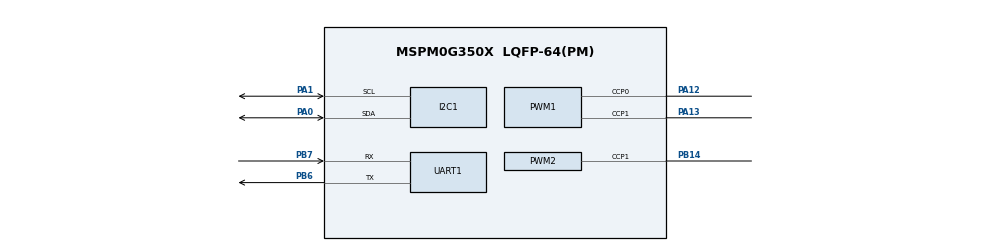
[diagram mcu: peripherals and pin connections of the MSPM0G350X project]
/**
 *
 * @cliArgs --device "MSPM0G350X" --part "Default" --package "LQFP-64(PM)" --product "mspm0_sdk@2.11.00.07"
 * @versions {"tool":"1.28.0+4712"}
 */

/**
 * Import the modules used in this configuration.
 */
const ADC12         = scripting.addModule("/ti/driverlib/ADC12", {}, false);
const ADC121        = ADC12.addInstance();
const Board         = scripting.addModule("/ti/driverlib/Board");
const GPIO          = scripting.addModule("/ti/driverlib/GPIO", {}, false);
const GPIO1         = GPIO.addInstance();
const GPIO2         = GPIO.addInstance();
const GPIO3         = GPIO.addInstance();
const I2C           = scripting.addModule("/ti/driverlib/I2C", {}, false);
const I2C1          = I2C.addInstance();
const PWM           = scripting.addModule("/ti/driverlib/PWM", {}, false);
const PWM1          = PWM.addInstance();
const PWM2          = PWM.addInstance();
const SYSCTL        = scripting.addModule("/ti/driverlib/SYSCTL");
const SYSTICK       = scripting.addModule("/ti/driverlib/SYSTICK");
const UART          = scripting.addModule("/ti/driverlib/UART", {}, false);
const UART1         = UART.addInstance();
const ProjectConfig = scripting.addModule("/ti/project_config/ProjectConfig");

/**
 * Write custom configuration values to the imported modules.
 */
ADC121.$name                             = "LINE_ADC";
ADC121.sampClkSrc                        = "DL_ADC12_CLOCK_ULPCLK";
ADC121.sampClkDiv                        = "DL_ADC12_CLOCK_DIVIDE_8";
ADC121.samplingOperationMode             = "sequence";
ADC121.endAdd                            = 4;
ADC121.adcMem0_name                      = "LEFT_2";
ADC121.adcMem1_name                      = "LEFT_1";
ADC121.adcMem1chansel                    = "DL_ADC12_INPUT_CHAN_2";
ADC121.adcMem2_name                      = "CENTER";
ADC121.adcMem2chansel                    = "DL_ADC12_INPUT_CHAN_3";
ADC121.adcMem3_name                      = "RIGHT_1";
ADC121.adcMem3chansel                    = "DL_ADC12_INPUT_CHAN_5";
ADC121.adcMem4_name                      = "RIGHT_2";
ADC121.adcMem4chansel                    = "DL_ADC12_INPUT_CHAN_7";
ADC121.powerDownMode                     = "DL_ADC12_POWER_DOWN_MODE_MANUAL";
ADC121.sampleTime0                       = "125 us";
ADC121.adcPin0Config.hideOutputInversion = scripting.forceWrite(false);
ADC121.adcPin0Config.$name               = "ti_driverlib_gpio_GPIOPinGeneric6";
ADC121.adcPin2Config.$name               = "ti_driverlib_gpio_GPIOPinGeneric7";
ADC121.adcPin3Config.$name               = "ti_driverlib_gpio_GPIOPinGeneric8";
ADC121.adcPin5Config.$name               = "ti_driverlib_gpio_GPIOPinGeneric9";
ADC121.adcPin7Config.$name               = "ti_driverlib_gpio_GPIOPinGeneric10";


GPIO1.$name                                 = "MOTOR_CONTROL";
GPIO1.associatedPins.create(4);
GPIO1.associatedPins[0].$name               = "AIN1";
GPIO1.associatedPins[0].assignedPort        = "PORTA";
GPIO1.associatedPins[0].assignedPortSegment = "Upper";
GPIO1.associatedPins[0].assignedPin         = "16";
GPIO1.associatedPins[1].$name               = "AIN2";
GPIO1.associatedPins[1].assignedPort        = "PORTB";
GPIO1.associatedPins[1].assignedPortSegment = "Upper";
GPIO1.associatedPins[1].assignedPin         = "24";
GPIO1.associatedPins[2].$name               = "BIN1";
GPIO1.associatedPins[2].assignedPort        = "PORTB";
GPIO1.associatedPins[2].assignedPortSegment = "Upper";
GPIO1.associatedPins[2].assignedPin         = "17";
GPIO1.associatedPins[3].$name               = "BIN2";
GPIO1.associatedPins[3].assignedPort        = "PORTB";
GPIO1.associatedPins[3].assignedPortSegment = "Upper";
GPIO1.associatedPins[3].assignedPin         = "19";

GPIO2.$name                                 = "GPIO_ENCODER";
GPIO2.associatedPins.create(4);
GPIO2.associatedPins[0].$name               = "LEFT_ENCODER_A";
GPIO2.associatedPins[0].direction           = "INPUT";
GPIO2.associatedPins[0].assignedPort        = "PORTA";
GPIO2.associatedPins[0].assignedPortSegment = "Lower";
GPIO2.associatedPins[0].assignedPin         = "14";
GPIO2.associatedPins[0].internalResistor    = "PULL_UP";
GPIO2.associatedPins[0].interruptEn         = true;
GPIO2.associatedPins[0].polarity            = "RISE_FALL";
GPIO2.associatedPins[1].$name               = "LEFT_ENCODER_B";
GPIO2.associatedPins[1].direction           = "INPUT";
GPIO2.associatedPins[1].assignedPort        = "PORTA";
GPIO2.associatedPins[1].assignedPortSegment = "Upper";
GPIO2.associatedPins[1].assignedPin         = "25";
GPIO2.associatedPins[1].internalResistor    = "PULL_UP";
GPIO2.associatedPins[1].interruptEn         = true;
GPIO2.associatedPins[1].polarity            = "RISE_FALL";
GPIO2.associatedPins[2].$name               = "RIGHT_ENCODER_A";
GPIO2.associatedPins[2].direction           = "INPUT";
GPIO2.associatedPins[2].assignedPort        = "PORTA";
GPIO2.associatedPins[2].assignedPortSegment = "Upper";
GPIO2.associatedPins[2].assignedPin         = "26";
GPIO2.associatedPins[2].internalResistor    = "PULL_UP";
GPIO2.associatedPins[2].interruptEn         = true;
GPIO2.associatedPins[2].polarity            = "RISE_FALL";
GPIO2.associatedPins[3].$name               = "RIGHT_ENCODER_B";
GPIO2.associatedPins[3].direction           = "INPUT";
GPIO2.associatedPins[3].assignedPort        = "PORTA";
GPIO2.associatedPins[3].assignedPortSegment = "Upper";
GPIO2.associatedPins[3].assignedPin         = "27";
GPIO2.associatedPins[3].internalResistor    = "PULL_UP";
GPIO2.associatedPins[3].interruptEn         = true;
GPIO2.associatedPins[3].polarity            = "RISE_FALL";

/*
 * The PCB OLED is wired for bit-banged open-drain I2C.  Inputs with pull-ups
 * represent the released/high bus state until the OLED driver takes control.
 */
GPIO3.$name                              = "OLED_I2C_GPIO";
GPIO3.port                               = "PORTA";
GPIO3.portSegment                        = "Upper";
GPIO3.associatedPins.create(2);
GPIO3.associatedPins[0].$name            = "SCL";
GPIO3.associatedPins[0].direction        = "INPUT";
GPIO3.associatedPins[0].assignedPin      = "31";
GPIO3.associatedPins[0].internalResistor = "PULL_UP";
GPIO3.associatedPins[1].$name            = "SDA";
GPIO3.associatedPins[1].direction        = "INPUT";
GPIO3.associatedPins[1].assignedPin      = "28";
GPIO3.associatedPins[1].internalResistor = "PULL_UP";

I2C1.$name                             = "MPU6050_I2C";
I2C1.basicEnableController             = true;
I2C1.basicControllerStandardBusSpeed   = "Fast";
I2C1.intController                     = ["ARBITRATION_LOST","NACK","RXFIFO_TRIGGER","RX_DONE","TX_DONE"];
I2C1.peripheral.$assign                = "I2C0";
I2C1.peripheral.sdaPin.$assign         = "PA0";
I2C1.peripheral.sclPin.$assign         = "PA1";
I2C1.sdaPinConfig.hideOutputInversion  = scripting.forceWrite(false);
I2C1.sdaPinConfig.onlyInternalResistor = scripting.forceWrite(false);
I2C1.sdaPinConfig.passedPeripheralType = scripting.forceWrite("Digital");
I2C1.sdaPinConfig.$name                = "ti_driverlib_gpio_GPIOPinGeneric4";
I2C1.sclPinConfig.hideOutputInversion  = scripting.forceWrite(false);
I2C1.sclPinConfig.onlyInternalResistor = scripting.forceWrite(false);
I2C1.sclPinConfig.passedPeripheralType = scripting.forceWrite("Digital");
I2C1.sclPinConfig.$name                = "ti_driverlib_gpio_GPIOPinGeneric5";

PWM1.$name                              = "MOTOR_PWM";
PWM1.timerCount                         = 1600;
PWM1.peripheral.$assign                 = "TIMG0";
/* PCB assignment: CCP0/PA12 = right motor, CCP1/PA13 = left motor. */
PWM1.peripheral.ccp0Pin.$assign         = "PA12";
PWM1.peripheral.ccp1Pin.$assign         = "PA13";
PWM1.PWM_CHANNEL_0.$name                = "ti_driverlib_pwm_PWMTimerCC0";
PWM1.PWM_CHANNEL_1.$name                = "ti_driverlib_pwm_PWMTimerCC1";
PWM1.ccp0PinConfig.direction            = scripting.forceWrite("OUTPUT");
PWM1.ccp0PinConfig.hideOutputInversion  = scripting.forceWrite(false);
PWM1.ccp0PinConfig.onlyInternalResistor = scripting.forceWrite(false);
PWM1.ccp0PinConfig.passedPeripheralType = scripting.forceWrite("Digital");
PWM1.ccp0PinConfig.$name                = "ti_driverlib_gpio_GPIOPinGeneric0";
PWM1.ccp1PinConfig.direction            = scripting.forceWrite("OUTPUT");
PWM1.ccp1PinConfig.hideOutputInversion  = scripting.forceWrite(false);
PWM1.ccp1PinConfig.onlyInternalResistor = scripting.forceWrite(false);
PWM1.ccp1PinConfig.passedPeripheralType = scripting.forceWrite("Digital");
PWM1.ccp1PinConfig.$name                = "ti_driverlib_gpio_GPIOPinGeneric1";

PWM2.$name                      = "SERVO_PWM";
PWM2.ccIndex                    = [1];
PWM2.timerCount                 = 640000;
PWM2.ccp1PinConfig.$name        = "ti_driverlib_gpio_GPIOPinGeneric15";
PWM2.peripheral.$assign         = "TIMG12";
PWM2.peripheral.ccp1Pin.$assign = "PB14";
PWM2.PWM_CHANNEL_1.$name        = "ti_driverlib_pwm_PWMTimerCC2";

SYSCTL.forceDefaultClkConfig = true;

SYSTICK.periodEnable    = true;
SYSTICK.period          = 32000;
SYSTICK.interruptEnable = true;
SYSTICK.systickEnable   = true;

UART1.$name                            = "HC05_UART";
UART1.targetBaudRate                   = 115200;
UART1.enabledInterrupts                = ["RX"];
UART1.peripheral.$assign               = "UART1";
UART1.peripheral.rxPin.$assign         = "PB7";
UART1.peripheral.txPin.$assign         = "PB6";
UART1.txPinConfig.direction            = scripting.forceWrite("OUTPUT");
UART1.txPinConfig.hideOutputInversion  = scripting.forceWrite(false);
UART1.txPinConfig.onlyInternalResistor = scripting.forceWrite(false);
UART1.txPinConfig.passedPeripheralType = scripting.forceWrite("Digital");
UART1.txPinConfig.$name                = "ti_driverlib_gpio_GPIOPinGeneric2";
UART1.rxPinConfig.hideOutputInversion  = scripting.forceWrite(false);
UART1.rxPinConfig.onlyInternalResistor = scripting.forceWrite(false);
UART1.rxPinConfig.passedPeripheralType = scripting.forceWrite("Digital");
UART1.rxPinConfig.$name                = "ti_driverlib_gpio_GPIOPinGeneric3";

ProjectConfig.compiler = "gcc";

/**
 * Pinmux solution for unlocked pins/peripherals. This ensures that minor changes to the automatic solver in a future
 * version of the tool will not impact the pinmux you originally saw.  These lines can be completely deleted in order to
 * re-solve from scratch.
 */
ADC121.peripheral.$assign                    = "ADC1";
ADC121.peripheral.adcPin0.$assign            = "PA15";
ADC121.peripheral.adcPin2.$assign            = "PA17";
ADC121.peripheral.adcPin3.$assign            = "PA18";
ADC121.peripheral.adcPin5.$assign            = "PB18";
ADC121.peripheral.adcPin7.$assign            = "PA21";
Board.peripheral.$suggestSolution            = "DEBUGSS";
Board.peripheral.swclkPin.$suggestSolution   = "PA20";
Board.peripheral.swdioPin.$suggestSolution   = "PA19";
GPIO1.associatedPins[0].pin.$suggestSolution = "PA16";
GPIO1.associatedPins[1].pin.$suggestSolution = "PB24";
GPIO1.associatedPins[2].pin.$suggestSolution = "PB17";
GPIO1.associatedPins[3].pin.$suggestSolution = "PB19";
GPIO2.associatedPins[0].pin.$suggestSolution = "PA14";
GPIO2.associatedPins[1].pin.$suggestSolution = "PA25";
GPIO2.associatedPins[2].pin.$suggestSolution = "PA26";
GPIO2.associatedPins[3].pin.$suggestSolution = "PA27";
GPIO3.associatedPins[0].pin.$suggestSolution = "PA31";
GPIO3.associatedPins[1].pin.$suggestSolution = "PA28";
SYSCTL.peripheral.$suggestSolution           = "SYSCTL";
